# R7FA4L1BD register map
Vendor: Renesas Electronics Corporation; Series: RA4; File version: 0.90.02
CPU: CM33 r0p4, little endian, MPU, FPU, VTOR, 4 interrupt priority bits, 96 interrupts
Registers are 32-bit, read-write, reset 0x0 unless marked. A register's access mark holds for its fields unless they carry their own. Offsets are from the block's base; [hi:lo] are bit positions; {n}, {i} and the like mark numbered series.

## I3C
Base 0x4011F000
0x00 PRTS reset 0x1 — Protocol Selection Register
  [0] PRTMD — Protocol Mode
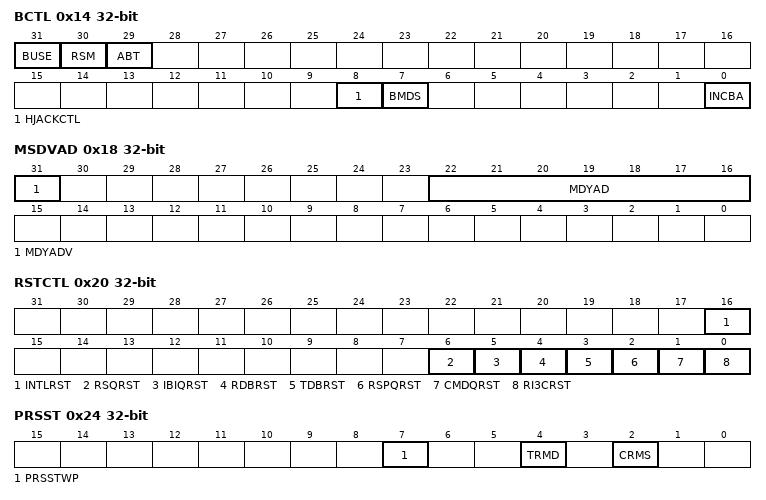
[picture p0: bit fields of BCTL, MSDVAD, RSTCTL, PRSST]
0x14 BCTL — Bus Control Register
  [31] BUSE — Bus Enable
  [30] RSM — Resume
  [29] ABT — Abort
  [8] HJACKCTL — Hot,Join Acknowledge Control
  [7] BMDS — Bus Mode Selection
  [0] INCBA — Include I3C Broadcast Address
0x18 MSDVAD — Master Device Address Register
  [31] MDYADV — Master Dynamic Address Valid
  [22:16] MDYAD — Master Dynamic Address
0x20 RSTCTL — Reset Control Register
  [16] INTLRST — Internal Software Reset
  [6] RSQRST — Normal Receive Status Queue Software Reset
  [5] IBIQRST — Normal IBI Queue Software Reset
  [4] RDBRST — Normal Rx Data Buffer Software Reset
  [3] TDBRST — Normal Tx Data Buffer Software Reset
  [2] RSPQRST — Normal Response Queue Software Reset
  [1] CMDQRST — Normal Command Queue Software Reset
  [0] RI3CRST — I3C Software Reset
0x24 PRSST — Present State Register
  [7] PRSSTWP wo — Present State Write Protect
  [4] TRMD ro — Transmit/Receive Mode
  [2] CRMS — Current Master
0x30 INST — Internal Status Register
  [10] INEF — Internal Error Flag
0x34 INSTE — Internal Status Enable Register
  [10] INEE — Internal Error Enable
0x38 INIE — Internal Interrupt Enable Register
  [10] INEIE — Internal Error Interrupt Enable
0x3C INSTFC wo — Internal Status Force Register
  [10] INEFC — Internal Error Force
0x44 DVCT ro — Device Characteristic Table Register
  [23:19] IDX — DCT Table Index
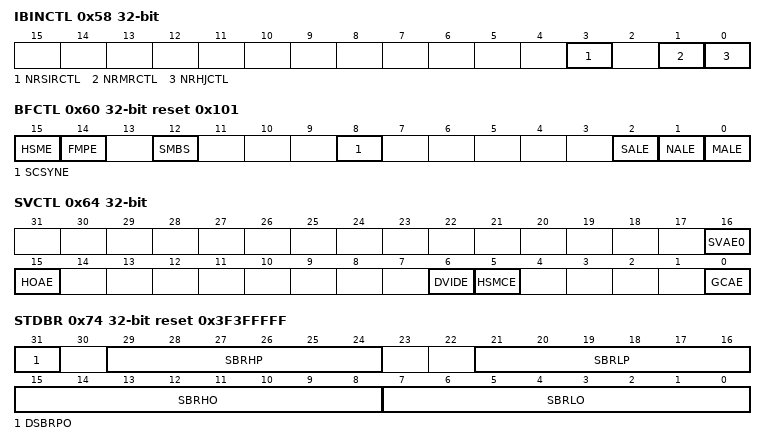
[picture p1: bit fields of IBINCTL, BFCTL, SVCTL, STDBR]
0x58 IBINCTL — IBI Notify Control Register
  [3] NRSIRCTL — Notify Rejected Slave Interrupt Request Control
  [1] NRMRCTL — Notify Rejected Master Request Control
  [0] NRHJCTL — Notify Rejected Hot,Join Control
0x60 BFCTL reset 0x101 — Bus Function Control Register
  [15] HSME — High Speed Mode Enable
  [14] FMPE — Fast,mode Plus Enable
  [12] SMBS — SMBus/I2C Bus Selection
  [8] SCSYNE — SCL Synchronous Circuit Enable
  [2] SALE — Slave Arbitration,Lost Detection Enable
  [1] NALE — NACK Transmission Arbitration,Lost Detection Enable
  [0] MALE — Master Arbitration,Lost Detection Enable
0x64 SVCTL — Slave Control Register
  [16] SVAE0 — Slave Address Enable 0
  [15] HOAE — Host Address Enable
  [6] DVIDE — Device,ID Address Enable
  [5] HSMCE — Hs,mode Master Code Enable
  [0] GCAE — General Call Address Enable
0x70 REFCKCTL — Reference Clock Control Register
  [2:0] IREFCKS — Internal Reference Clock Selection
0x74 STDBR reset 0x3F3FFFFF — Standard Bit Rate Register
  [31] DSBRPO — Double the Standard Bit Rate Period for Open,Drain
  [29:24] SBRHP — Standard Bit Rate High,Level Period Push,Pull
  [21:16] SBRLP — Standard Bit Rate Low,level Period Push,Pull
  [15:8] SBRHO — Standard Bit Rate High,Level Period Open,Drain
  [7:0] SBRLO — Standard Bit Rate Low,Level Period Open,Drain
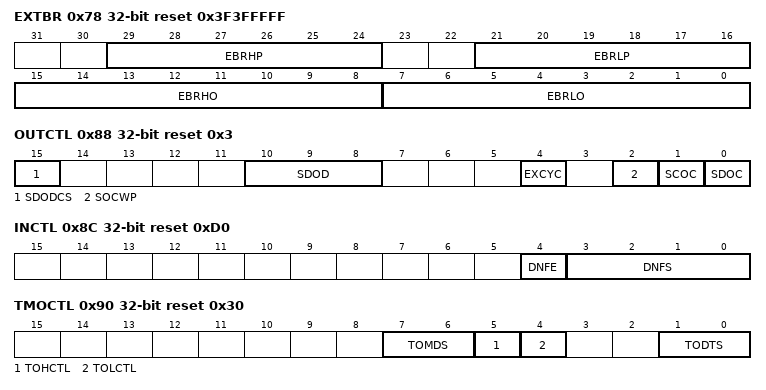
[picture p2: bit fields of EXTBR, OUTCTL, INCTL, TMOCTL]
0x78 EXTBR reset 0x3F3FFFFF — Extended Bit Rate Register
  [29:24] EBRHP — Extended Bit Rate High,Level Period Push,Pull
  [21:16] EBRLP — Extended Bit Rate Low,Level Period Push,Pull
  [15:8] EBRHO — Extended Bit Rate High,Level Period Open,Drain
  [7:0] EBRLO — Extended Bit Rate Low,Level Period Open,Drain
0x7C BFRECDT — Bus Free Condition Detection Time Register
  [8:0] FRECYC — Bus Free Condition Detection Cycle
0x80 BAVLCDT — Bus Available Condition Detection Time Register
  [8:0] AVLCYC — Bus Available Condition Detection Cycle
0x84 BIDLCDT — Bus Idle Condition Detection Time Register
  [17:0] IDLCYC — Bus Idle Condition Detection Cycle
0x88 OUTCTL reset 0x3 — Output Control Register
  [15] SDODCS — SDA Output Delay Clock Source Selection
  [10:8] SDOD — SDA Output Delay
  [4] EXCYC — Extra SCL Clock Cycle Output
  [2] SOCWP wo — SCL/SDA Output Control Write Protect
  [1] SCOC — SCL Output Control
  [0] SDOC — SDA Output Control
0x8C INCTL reset 0xD0 — Input Control Register
  [4] DNFE — Digital Noise Filter Circuit Enable
  [3:0] DNFS — Digital Noise Filter Stage Selection
0x90 TMOCTL reset 0x30 — Timeout Control Register
  [7:6] TOMDS — Timeout Operation Mode Selection
  [5] TOHCTL — Timeout H Count Control
  [4] TOLCTL — Timeout L Count Control
  [1:0] TODTS — Timeout Detection Time Selection
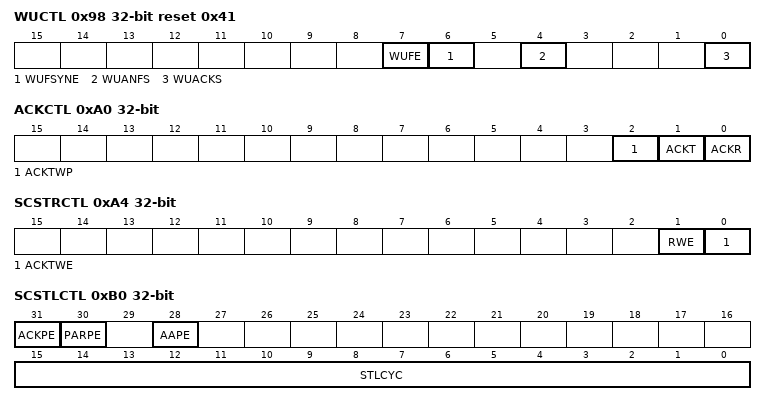
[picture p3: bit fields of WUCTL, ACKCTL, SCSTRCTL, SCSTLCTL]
0x98 WUCTL reset 0x41 — Wake,up Unit Control Register
  [7] WUFE — Wake,up function Enable
  [6] WUFSYNE — Wake,up function PCLK Synchronous Enable
  [4] WUANFS — Wake,up Analog Noise Filter Selection
  [0] WUACKS — Wake,up Acknowledge Selection
0xA0 ACKCTL — Acknowledge Control Register
  [2] ACKTWP wo — ACKT Write Protect
  [1] ACKT — Acknowledge Transmission
  [0] ACKR ro — Acknowledge Reception
0xA4 SCSTRCTL — SCL Stretch Control Register
  [1] RWE — Receive Wait Enable
  [0] ACKTWE — Acknowledge Transmission Wait Enable
0xB0 SCSTLCTL — SCL Stalling Control Register
  [31] ACKPE — ACK phase Enable
  [30] PARPE — Parity Phase Enable
  [28] AAPE — Assigned Address Phase Enable
  [15:0] STLCYC — Stalling Cycle
0xC0 SVTDLG0 — Slave Transfer Data Length Register 0
  [31:16] STDLG — Slave Transfer Data Length
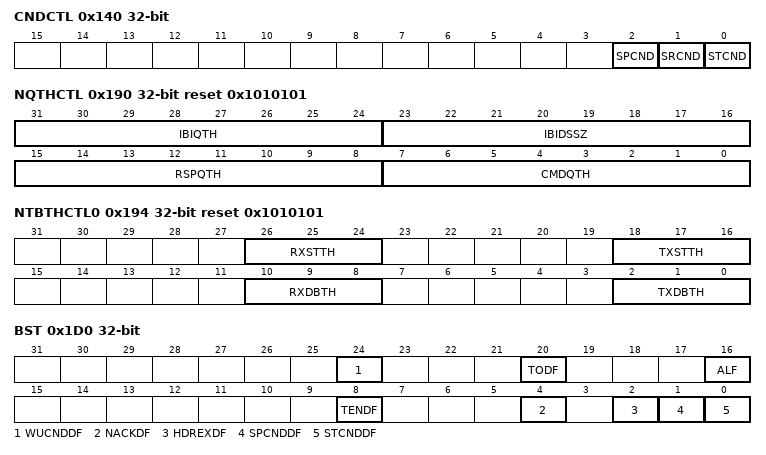
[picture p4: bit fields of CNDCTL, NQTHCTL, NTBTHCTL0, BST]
0x140 CNDCTL — Condition Control Register
  [2] SPCND — STOP (P) Condition Issuance
  [1] SRCND — Repeated START (Sr) Condition Issuance
  [0] STCND — START (S) Condition Issuance
0x150 NCMDQP wo — Normal Command Queue Port Register
0x154 NRSPQP ro — Normal Response Queue Port Register
0x158 NTDTBP0 — Normal Transfer Data Buffer Port Register 0
0x158 NTDTBP0_BY 8-bit (alternate view of NTDTBP0) — Normal Transfer Data Buffer Port Register 0
0x17C NIBIQP — Normal IBI Queue Port Register
0x180 NRSQP ro — Normal Receive Status Queue Port Register
0x190 NQTHCTL reset 0x1010101 — Normal Queue Threshold Control Register
  [31:24] IBIQTH — Normal IBI Queue Threshold
  [23:16] IBIDSSZ — Normal IBI Data Segment Size
  [15:8] RSPQTH — Normal Response Queue Threshold
  [7:0] CMDQTH — Normal Command Queue Threshold
0x194 NTBTHCTL0 reset 0x1010101 — Normal Transfer Data Buffer Threshold Control Register 0
  [26:24] RXSTTH — Normal Rx Start Threshold
  [18:16] TXSTTH — Normal Tx Start Threshold
  [10:8] RXDBTH — Normal Rx Data Buffer Threshold
  [2:0] TXDBTH — Normal Tx Data Buffer Threshold
0x1C0 NRQTHCTL reset 0x1 — Normal Receive Status Queue Threshold Control Register
  [7:0] RSQTH — Normal Receive Status Queue Threshold
0x1D0 BST — Bus Status Register
  [24] WUCNDDF — Wake,up Condition Detection Flag
  [20] TODF — Timeout Detection Flag
  [16] ALF — Arbitration Lost Flag
  [8] TENDF — Transmit End Flag
  [4] NACKDF — NACK Detection Flag
  [2] HDREXDF — HDR Exit Pattern Detection Flag
  [1] SPCNDDF — STOP Condition Detection Flag
  [0] STCNDDF — START Condition Detection Flag
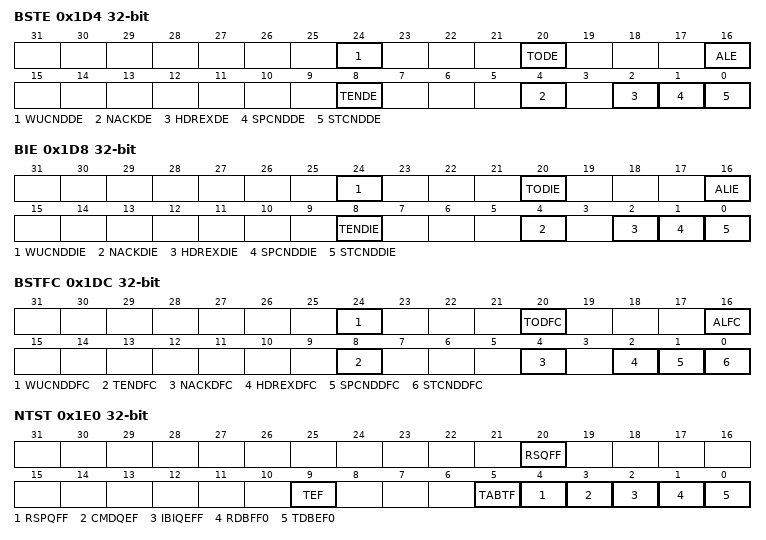
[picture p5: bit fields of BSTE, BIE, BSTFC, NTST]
0x1D4 BSTE — Bus Status Enable Register
  [24] WUCNDDE — Wake,up Condition Detection Enable
  [20] TODE — Timeout Detection Enable
  [16] ALE — Arbitration Lost Enable
  [8] TENDE — Transmit End Enable
  [4] NACKDE — NACK Detection Enable
  [2] HDREXDE — HDR Exit Pattern Detection Enable
  [1] SPCNDDE — STOP Condition Detection Enable
  [0] STCNDDE — START Condition Detection Enable
0x1D8 BIE — Bus Interrupt Enable Register
  [24] WUCNDDIE — Wake,up Condition Detection Interrupt Enable
  [20] TODIE — Timeout Detection Interrupt Enable
  [16] ALIE — Arbitration Lost Interrupt Enable
  [8] TENDIE — Transmit End Interrupt Enable
  [4] NACKDIE — NACK Detection Interrupt Enable
  [2] HDREXDIE — HDR Exit Pattern Detection Interrupt Enable
  [1] SPCNDDIE — STOP Condition Detection Interrupt Enable
  [0] STCNDDIE — START Condition Detection Interrupt Enable
0x1DC BSTFC — Bus Status Force Register
  [24] WUCNDDFC wo — Wake,up Condition Detection Force
  [20] TODFC wo — Timeout Detection Force
  [16] ALFC wo — Arbitration Lost Force
  [8] TENDFC wo — Transmit End Force
  [4] NACKDFC wo — NACK Detection Force
  [2] HDREXDFC wo — HDR Exit Pattern Detection Force
  [1] SPCNDDFC wo — STOP condition Detection Force
  [0] STCNDDFC wo — START condition Detection Force
0x1E0 NTST — Normal Transfer Status Register
  [20] RSQFF — Normal Receive Status Queue Full Flag
  [9] TEF — Normal Transfer Error Flag
  [5] TABTF — Normal Transfer Abort Flag
  [4] RSPQFF — Normal Response Queue Full Flag
  [3] CMDQEF — Normal Command Queue Empty Flag
  [2] IBIQEFF — Normal IBI Queue Empty/Full Flag
  [1] RDBFF0 — Normal Rx Data Buffer Full Flag 0
  [0] TDBEF0 — Normal Tx Data Buffer Empty Flag 0
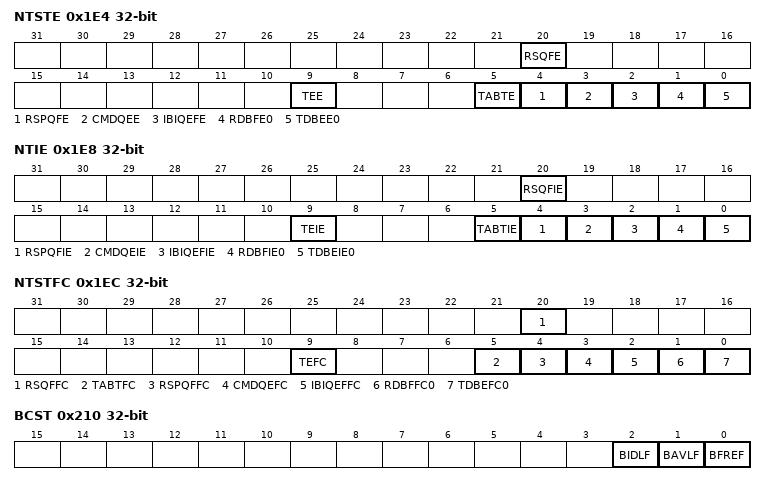
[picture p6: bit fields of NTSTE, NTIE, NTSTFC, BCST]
0x1E4 NTSTE — Normal Transfer Status Enable Register
  [20] RSQFE — Normal Receive Status Queue Full Enable
  [9] TEE — Normal Transfer Error Enable
  [5] TABTE — Normal Transfer Abort Enable
  [4] RSPQFE — Normal Response Queue Full Enable
  [3] CMDQEE — Normal Command Queue Empty Enable
  [2] IBIQEFE — Normal IBI Queue Empty/Full Enable
  [1] RDBFE0 — Normal Rx Data Buffer Full Enable 0
  [0] TDBEE0 — Normal Tx Data Buffer Empty Enable 0
0x1E8 NTIE — Normal Transfer Interrupt Enable Register
  [20] RSQFIE — Normal Receive Status Queue Full Interrupt Enable
  [9] TEIE — Normal Transfer Error Interrupt Enable
  [5] TABTIE — Normal Transfer Abort Interrupt Enable
  [4] RSPQFIE — Normal Response Queue Full Interrupt Enable
  [3] CMDQEIE — Normal Command Queue Empty Interrupt Enable
  [2] IBIQEFIE — Normal IBI Queue Empty/Full Interrupt Enable
  [1] RDBFIE0 — Normal Rx Data Buffer Full Interrupt Enable 0
  [0] TDBEIE0 — Normal Tx Data Buffer Empty Interrupt Enable 0
0x1EC NTSTFC — Normal Transfer Status Force Register
  [20] RSQFFC wo — Normal Receive Status Queue Full Force
  [9] TEFC wo — Normal Transfer Error Force
  [5] TABTFC wo — Normal Transfer Abort Force
  [4] RSPQFFC wo — Normal Response Queue Full Force
  [3] CMDQEFC wo — Normal Command Queue Empty Force
  [2] IBIQEFFC wo — Normal IBI Queue Empty/Full Force
  [1] RDBFFC0 wo — Normal Rx Data Buffer Full Force 0
  [0] TDBEFC0 wo — Normal Tx Data Buffer Empty Force 0
0x210 BCST ro — Bus Condition Status Register
  [2] BIDLF — Bus Idle Detection Flag
  [1] BAVLF — Bus Available Detection Flag
  [0] BFREF — Bus Free Detection Flag
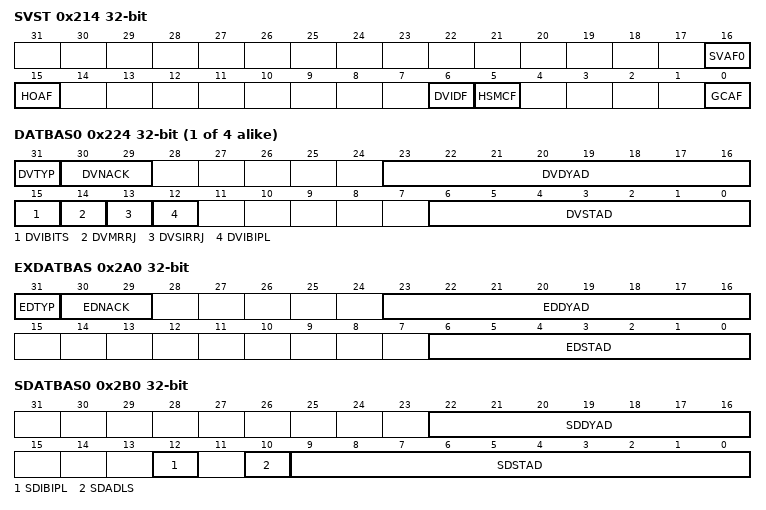
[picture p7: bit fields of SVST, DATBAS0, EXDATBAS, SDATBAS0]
0x214 SVST — Slave Status Register
  [16] SVAF0 — Slave Address Detection Flag 0
  [15] HOAF — Host Address Detection Flag
  [6] DVIDF — Device,ID Address Detection Flag
  [5] HSMCF — Hs,mode Master Code Detection Flag
  [0] GCAF — General Call Address Detection Flag
0x218 WUST ro — Wake,up Unit Operating Status Register
  [0] WUASYNF — Wake,up function asynchronous operation status flag
{0x224+8i} DATBAS{i} (i=0..3) — Device Address Table Basic Register {i}
  [31] DVTYP — Device Type
  [30:29] DVNACK — Device NACK Retry Count
  [23:16] DVDYAD — Device I3C Dynamic Address
  [15] DVIBITS — Device IBI Time,stamp
  [14] DVMRRJ — Device In,Band Master Request Reject
  [13] DVSIRRJ — Device In,Band Slave Interrupt Request Reject
  [12] DVIBIPL — Device IBI Payload
  [6:0] DVSTAD — Device Static Address
0x2A0 EXDATBAS — Extended Device Address Table Basic Register
  [31] EDTYP — Extended Device Type
  [30:29] EDNACK — Extended Device NACK Retry Count
  [23:16] EDDYAD — Extended Device I3C Dynamic Address
  [6:0] EDSTAD — Extended Device Static Address
0x2B0 SDATBAS0 — Slave Device Address Table Basic Register 0
  [22:16] SDDYAD — Slave Device I3C Dynamic Address
  [12] SDIBIPL — Slave Device IBI Payload
  [10] SDADLS — Slave Device Address Length Selection
  [9:0] SDSTAD — Slave Device Static Address
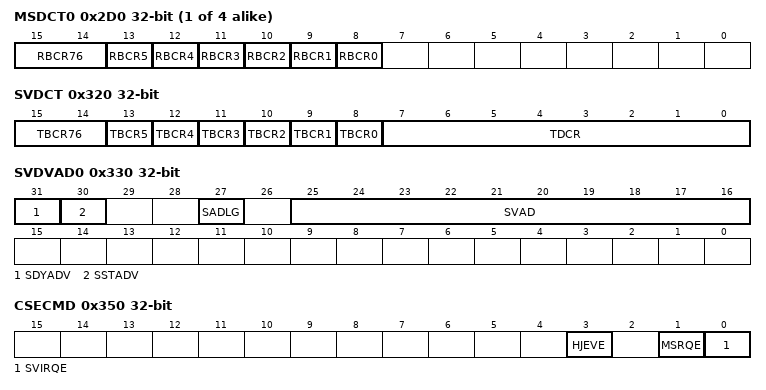
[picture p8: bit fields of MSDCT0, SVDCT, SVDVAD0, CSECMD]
{0x2D0+4i} MSDCT{i} (i=0..3) — Master Device Characteristic Table Register {i}
  [15:14] RBCR76 — Device Role
  [13] RBCR5 — SDR Only / SDR and HDR Capable
  [12] RBCR4 — Bridge Identifier
  [11] RBCR3 — Offline Capable
  [10] RBCR2 — IBI Payload
  [9] RBCR1 — IBI Request Capable
  [8] RBCR0 — Max Data Speed Limitation
0x320 SVDCT — Slave Device Characteristic Table Register
  [15:14] TBCR76 — Device Role
  [13] TBCR5 — SDR Only / SDR and HDR Capable
  [12] TBCR4 — Bridge Identifier
  [11] TBCR3 — Offline Capable
  [10] TBCR2 — IBI Payload
  [9] TBCR1 — IBI Request Capable
  [8] TBCR0 — Max Data Speed Limitation
  [7:0] TDCR — Transfer Device Characteristic Register
0x324 SDCTPIDL — Slave Device Characteristic Table Provisional ID Low Register
0x328 SDCTPIDH — Slave Device Characteristic Table Provisional ID High Register
0x330 SVDVAD0 ro — Slave Device Address Register 0
  [31] SDYADV — Slave Dynamic Address Valid
  [30] SSTADV — Slave Static Address Valid
  [27] SADLG — Slave Address Length
  [25:16] SVAD — Slave Address
0x350 CSECMD — CCC Slave Events Command Register
  [3] HJEVE — Hot,Join Event Enable
  [1] MSRQE — Mastership Requests Enable
  [0] SVIRQE — Slave Interrupt Requests Enable
0x354 CEACTST — CCC Enter Activity State Register
  [3:0] ACTST — Activity State
0x358 CMWLG — CCC Max Write Length Register
  [15:0] MWLG — Max Write Length
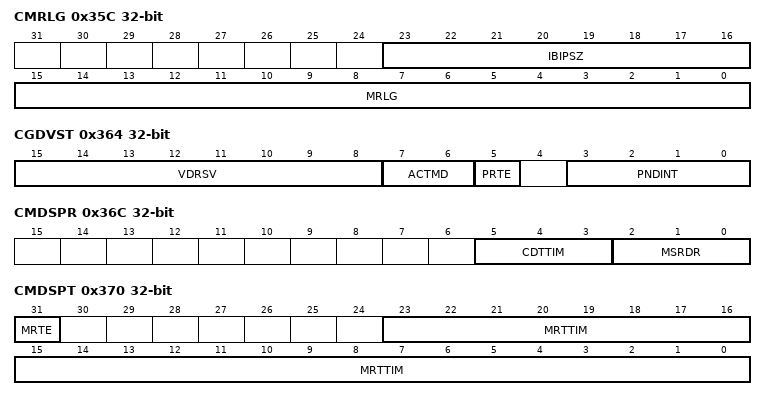
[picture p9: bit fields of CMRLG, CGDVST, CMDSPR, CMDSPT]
0x35C CMRLG — CCC Max Read Length Register
  [23:16] IBIPSZ — IBI Payload Size
  [15:0] MRLG — Max Read Length
0x360 CETSTMD ro — CCC Enter Test Mode Register
  [7:0] TSTMD — Test Mode
0x364 CGDVST — CCC Get Device Status Register
  [15:8] VDRSV — Vendor Reserved
  [7:6] ACTMD — Slave Device’s current Activity Mode
  [5] PRTE — Protocol Error
  [3:0] PNDINT — Pending Interrupt
0x368 CMDSPW — CCC Max Data Speed W (Write) Register
  [2:0] MSWDR — Maximum Sustained Write Data Rate
0x36C CMDSPR — CCC Max Data Speed R (Read) Register
  [5:3] CDTTIM — Clock to Data Turnaround Time (TSCO)
  [2:0] MSRDR — Maximum Sustained Read Data Rate
0x370 CMDSPT — CCC Max Data Speed T (Turnaround) Register
  [31] MRTE — Maximum Read Turnaround Time Enable
  [23:0] MRTTIM — Maximum Read Turnaround Time
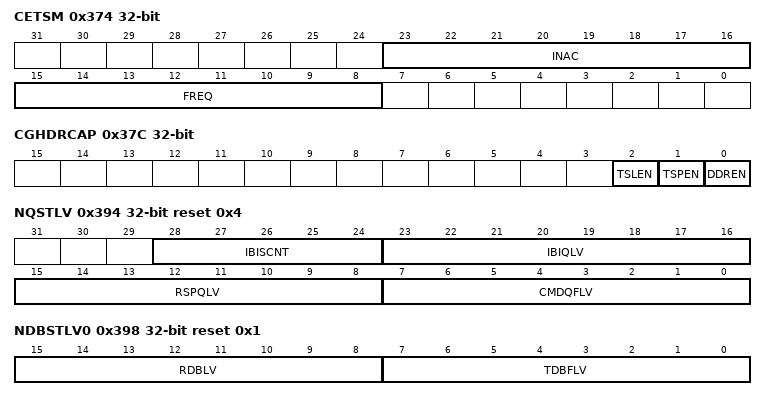
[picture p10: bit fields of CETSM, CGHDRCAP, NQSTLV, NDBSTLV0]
0x374 CETSM — CCC Exchange Timing Support Information M (Mode) Register
  [23:16] INAC — Inaccuracy Byte
  [15:8] FREQ — Frequency Byte
0x37C CGHDRCAP — CCC Get HDR Capability Register
  [2] TSLEN — HDR,TSL Operation Enable
  [1] TSPEN — HDR,TSP Operation Enable
  [0] DDREN — HDR,DDR Operation Enable
0x380 BITCNT ro — Bit Count Register
  [4:0] BCNT — Bit Counter
0x394 NQSTLV ro reset 0x4 — Normal Queue Status Level Register
  [28:24] IBISCNT — Normal IBI Status Count
  [23:16] IBIQLV — Normal IBI Queue Level
  [15:8] RSPQLV — Normal Response Queue Level
  [7:0] CMDQFLV — Normal Command Queue Free Level
0x398 NDBSTLV0 ro reset 0x1 — Normal Data Buffer Status Level Register 0
  [15:8] RDBLV — Normal Rx Data Buffer Level
  [7:0] TDBFLV — Normal Tx Data Buffer Free Level
0x3C0 NRSQSTLV ro — Normal Receive Status Queue Status Level Register
  [7:0] RSQLV — Normal Receive Status Queue Level
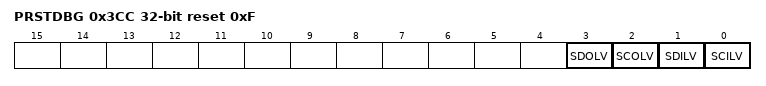
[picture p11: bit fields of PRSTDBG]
0x3CC PRSTDBG ro reset 0xF — Present State Debug Register
  [3] SDOLV — SDA Output Level
  [2] SCOLV — SCL Output Level
  [1] SDILV — I3C_SDA Line Signal Level
  [0] SCILV — I3C_SCL Line Signal Level
0x3D0 MSERRCNT ro — Master Error Counters Register
  [7:0] M2ECNT — M2 Error Counter
